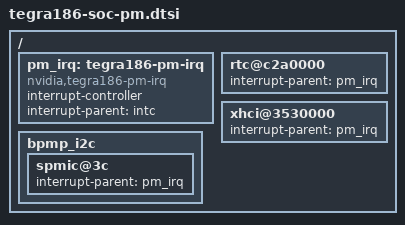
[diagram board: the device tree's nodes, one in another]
/*
 * Copyright (c) 2016, NVIDIA CORPORATION.  All rights reserved.
 *
 * This program is free software; you can redistribute it and/or modify
 * it under the terms of the GNU General Public License as published by
 * the Free Software Foundation; version 2 of the License.
 *
 * This program is distributed in the hope that it will be useful, but WITHOUT
 * ANY WARRANTY; without even the implied warranty of MERCHANTABILITY or
 * FITNESS FOR A PARTICULAR PURPOSE.  See the GNU General Public License for
 * more details.
 */

/ {
	pm_irq: tegra186-pm-irq {
		compatible = "nvidia,tegra186-pm-irq";
		interrupt-controller;
		#interrupt-cells = <3>;
		interrupt-parent = <&intc>;
	};

	rtc@c2a0000 {
		interrupt-parent = <&pm_irq>;
	};

	xhci@3530000 {
		interrupt-parent = <&pm_irq>;
	};

	bpmp_i2c {
		spmic@3c {
			interrupt-parent = <&pm_irq>;
		};
	};
};
